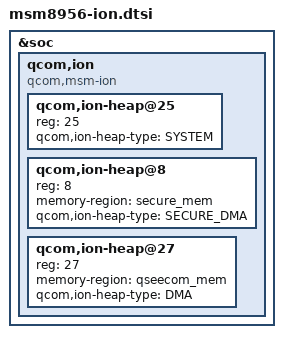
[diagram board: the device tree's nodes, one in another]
// SPDX-License-Identifier: GPL-2.0
// Copyright (c) 2014-2016, The Linux Foundation. All rights reserved.
// Copyright (c) 2022, Benarji Anand <benarji385@gmail.com>

&soc {
	qcom,ion {
		compatible = "qcom,msm-ion";
		#address-cells = <1>;
		#size-cells = <0>;

		qcom,ion-heap@25 {
			reg = <25>;
			qcom,ion-heap-type = "SYSTEM";
		};

		qcom,ion-heap@8 { /* CP_MM HEAP */
			reg = <8>;
			memory-region = <&secure_mem>;
			qcom,ion-heap-type = "SECURE_DMA";
		};

		qcom,ion-heap@27 { /* QSEECOM HEAP */
			reg = <27>;
			memory-region = <&qseecom_mem>;
			qcom,ion-heap-type = "DMA";
		};
	};
};
